# ATSAMD11D14AS device description
Architecture: CORTEX-M0PLUS; Family: SAMD; Series: SAMD11
Registers are 32-bit, read-write, reset 0x0 unless marked. A register's access mark holds for its fields unless they carry their own. Offsets are from the block's base; [hi:lo] are bit positions; lines under a group give offsets from that group; {n}, {i} and the like mark numbered series; 'fields as' and 'values as' point back to an identical list.

## USB — Universal Serial Bus
Instances: USB 0x41005000
0x00 DEVICE group (when USB.CTRLA.MODE=0) — Universal Serial Bus - USB is Device
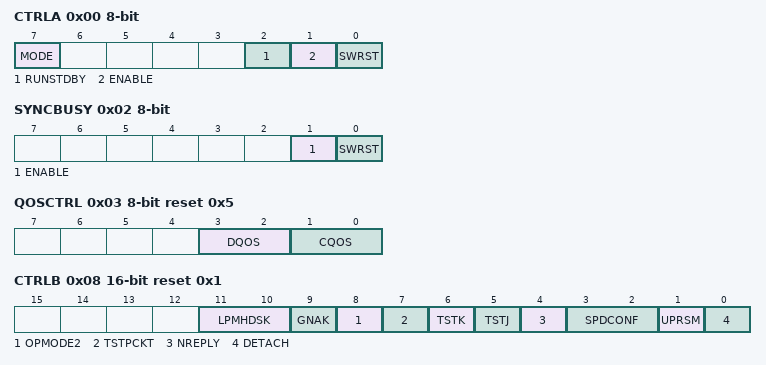
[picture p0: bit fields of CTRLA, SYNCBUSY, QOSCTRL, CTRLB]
  0x00 CTRLA 8-bit — Control A
    [7] MODE — Operating Mode
      0=DEVICE (Device Mode)
    [2] RUNSTDBY — Run in Standby Mode
    [1] ENABLE
    [0] SWRST — Software Reset
  0x02 SYNCBUSY 8-bit ro — Synchronization Busy
    [1] ENABLE — Enable Synchronization Busy
    [0] SWRST — Software Reset Synchronization Busy
  0x03 QOSCTRL 8-bit reset 0x5 — USB Quality Of Service
    [3:2] DQOS — Data Quality of Service
    [1:0] CQOS — Configuration Quality of Service
  0x08 CTRLB 16-bit reset 0x1 — DEVICE Control B
    [11:10] LPMHDSK — Link Power Management Handshake
      0=NO (No handshake. LPM is not supported); 1=ACK; 2=NYET; 3=STALL
    [9] GNAK — Global NAK
    [8] OPMODE2 — Specific Operational Mode
    [7] TSTPCKT — Test packet mode
    [6] TSTK — Test mode K
    [5] TSTJ — Test mode J
    [4] NREPLY — No Reply
    [3:2] SPDCONF — Speed Configuration
      0=FS (FS : Full Speed); 1=LS (LS : Low Speed); 2=HS (HS : High Speed capable); 3=HSTM (HSTM: High Speed Test Mode (force high-speed mode for test mode))
    [1] UPRSM — Upstream Resume
    [0] DETACH
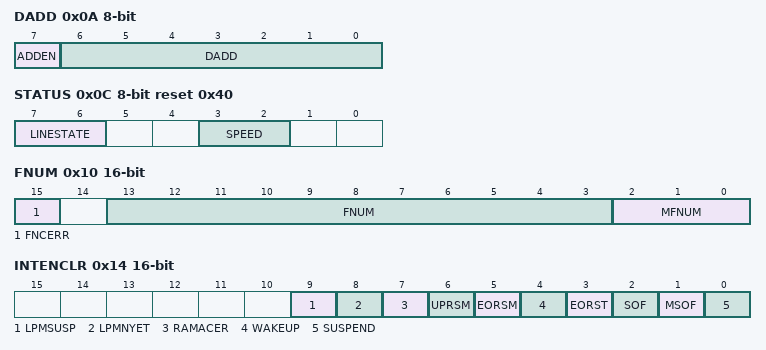
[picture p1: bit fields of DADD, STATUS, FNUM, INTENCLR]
  0x0A DADD 8-bit — DEVICE Device Address
    [7] ADDEN — Device Address Enable
    [6:0] DADD — Device Address
  0x0C STATUS 8-bit ro reset 0x40 — DEVICE Status
    [7:6] LINESTATE — USB Line State Status
      0=SE0/RESET; 1=FS-J or LS-K State; 2=FS-K or LS-J State
    [3:2] SPEED — Speed Status
      0=FS (Full-speed mode); 1=HS (High-speed mode); 2=LS (Low-speed mode)
  0x0D FSMSTATUS 8-bit ro reset 0x1 — Finite State Machine Status
    [5:0] FSMSTATE — Fine State Machine Status
      1=OFF (OFF (L3). It corresponds to the powered-off, disconnected, and disabled state); 2=ON (ON (L0). It corresponds to the Idle and Active states); 4=SUSPEND (SUSPEND (L2)); 8=SLEEP (SLEEP (L1)); 16=DNRESUME (DNRESUME. Down Stream Resume.); 32=UPRESUME (UPRESUME. Up Stream Resume.); 64=RESET (RESET. USB lines Reset.)
  0x10 FNUM 16-bit ro — DEVICE Device Frame Number
    [15] FNCERR — Frame Number CRC Error
    [13:3] FNUM — Frame Number
    [2:0] MFNUM — Micro Frame Number
  0x14 INTENCLR 16-bit (atomic clear) — DEVICE Device Interrupt Enable Clear
    [9] LPMSUSP — Link Power Management Suspend Interrupt Enable
    [8] LPMNYET — Link Power Management Not Yet Interrupt Enable
    [7] RAMACER — Ram Access Interrupt Enable
    [6] UPRSM — Upstream Resume Interrupt Enable
    [5] EORSM — End Of Resume Interrupt Enable
    [4] WAKEUP — Wake Up Interrupt Enable
    [3] EORST — End of Reset Interrupt Enable
    [2] SOF — Start Of Frame Interrupt Enable
    [1] MSOF — Micro Start of Frame Interrupt Enable in High Speed Mode
    [0] SUSPEND — Suspend Interrupt Enable
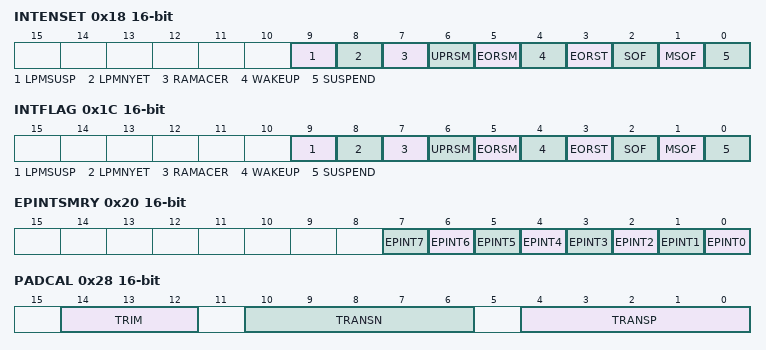
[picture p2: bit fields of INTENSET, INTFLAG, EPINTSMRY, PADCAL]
  0x18 INTENSET 16-bit (atomic set) — DEVICE Device Interrupt Enable Set
    fields as DEVICE.INTENCLR
  0x1C INTFLAG 16-bit (atomic clear) — DEVICE Device Interrupt Flag
    [9] LPMSUSP — Link Power Management Suspend
    [8] LPMNYET — Link Power Management Not Yet
    [7] RAMACER — Ram Access
    [6] UPRSM — Upstream Resume
    [5] EORSM — End Of Resume
    [4] WAKEUP
    [3] EORST — End of Reset
    [2] SOF — Start Of Frame
    [1] MSOF — Micro Start of Frame in High Speed Mode
    [0] SUSPEND
  0x20 EPINTSMRY 16-bit ro — DEVICE End Point Interrupt Summary
    [n] EPINT{n} (n=0..7) — End Point {n} Interrupt
  0x24 DESCADD — Descriptor Address
    [31:0] DESCADD — Descriptor Address Value
  0x28 PADCAL 16-bit — USB PAD Calibration
    [14:12] TRIM — USB Pad Trim calibration
    [10:6] TRANSN — USB Pad Transn calibration
    [4:0] TRANSP — USB Pad Transp calibration
  {0x100+0x20*j} DEVICE_ENDPOINT[{j}] (j=0..7) group
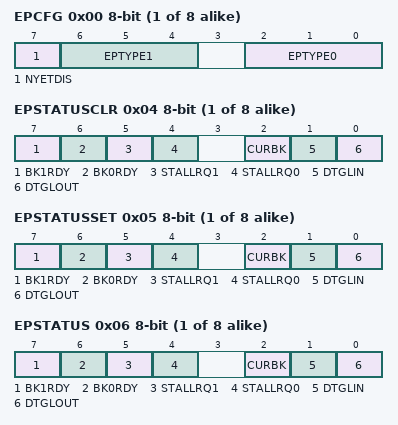
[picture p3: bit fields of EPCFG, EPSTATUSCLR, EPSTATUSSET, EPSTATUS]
    0x00 EPCFG 8-bit — DEVICE_ENDPOINT End Point Configuration
      [7] NYETDIS — NYET Token Disable
      [6:4] EPTYPE1 — End Point Type1
      [2:0] EPTYPE0 — End Point Type0
    0x04 EPSTATUSCLR 8-bit wo (atomic clear of EPSTATUS) — DEVICE_ENDPOINT End Point Pipe Status Clear
      [7] BK1RDY — Bank 1 Ready Clear
      [6] BK0RDY — Bank 0 Ready Clear
      [5] STALLRQ1 — Stall 1 Request Clear
      [4] STALLRQ0 — Stall 0 Request Clear
      [2] CURBK — Current Bank Clear
      [1] DTGLIN — Data Toggle IN Clear
      [0] DTGLOUT — Data Toggle OUT Clear
    0x05 EPSTATUSSET 8-bit wo (atomic set of EPSTATUS) — DEVICE_ENDPOINT End Point Pipe Status Set
      [7] BK1RDY — Bank 1 Ready Set
      [6] BK0RDY — Bank 0 Ready Set
      [5] STALLRQ1 — Stall 1 Request Set
      [4] STALLRQ0 — Stall 0 Request Set
      [2] CURBK — Current Bank Set
      [1] DTGLIN — Data Toggle IN Set
      [0] DTGLOUT — Data Toggle OUT Set
    0x06 EPSTATUS 8-bit ro — DEVICE_ENDPOINT End Point Pipe Status
      [7] BK1RDY — Bank 1 ready
      [6] BK0RDY — Bank 0 ready
      [5] STALLRQ1 — Stall 1 Request
      [4] STALLRQ0 — Stall 0 Request
      [2] CURBK — Current Bank
      [1] DTGLIN — Data Toggle In
      [0] DTGLOUT — Data Toggle Out
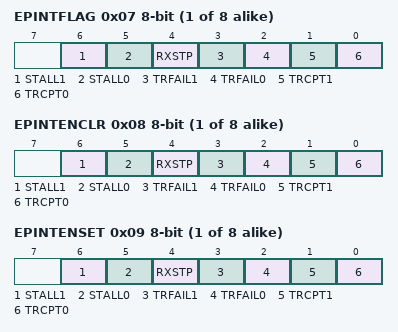
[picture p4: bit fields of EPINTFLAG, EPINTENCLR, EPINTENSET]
    0x07 EPINTFLAG 8-bit (atomic clear) — DEVICE_ENDPOINT End Point Interrupt Flag
      [6] STALL1 — Stall 1 In/out
      [5] STALL0 — Stall 0 In/out
      [4] RXSTP — Received Setup
      [3] TRFAIL1 — Error Flow 1
      [2] TRFAIL0 — Error Flow 0
      [1] TRCPT1 — Transfer Complete 1
      [0] TRCPT0 — Transfer Complete 0
    0x08 EPINTENCLR 8-bit (atomic clear) — DEVICE_ENDPOINT End Point Interrupt Clear Flag
      [6] STALL1 — Stall 1 In/Out Interrupt Disable
      [5] STALL0 — Stall 0 In/Out Interrupt Disable
      [4] RXSTP — Received Setup Interrupt Disable
      [3] TRFAIL1 — Error Flow 1 Interrupt Disable
      [2] TRFAIL0 — Error Flow 0 Interrupt Disable
      [1] TRCPT1 — Transfer Complete 1 Interrupt Disable
      [0] TRCPT0 — Transfer Complete 0 Interrupt Disable
    0x09 EPINTENSET 8-bit (atomic set) — DEVICE_ENDPOINT End Point Interrupt Set Flag
      [6] STALL1 — Stall 1 In/out Interrupt enable
      [5] STALL0 — Stall 0 In/out Interrupt enable
      [4] RXSTP — Received Setup Interrupt Enable
      [3] TRFAIL1 — Error Flow 1 Interrupt Enable
      [2] TRFAIL0 — Error Flow 0 Interrupt Enable
      [1] TRCPT1 — Transfer Complete 1 Interrupt Enable
      [0] TRCPT0 — Transfer Complete 0 Interrupt Enable

## Notices in the file
Copyright (c) 2016 Atmel Corporation,
a wholly owned subsidiary of Microchip Technology Inc.
Licensed under the Apache License, Version 2.0 (the "License");
you may not use this file except in compliance with the License.
You may obtain a copy of the Licence at
http://www.apache.org/licenses/LICENSE-2.0
Unless required by applicable law or agreed to in writing, software
distributed under the License is distributed on an "AS IS" BASIS,
WITHOUT WARRANTIES OR CONDITIONS OF ANY KIND, either express or implied.
See the License for the specific language governing permissions and
limitations under the License.
